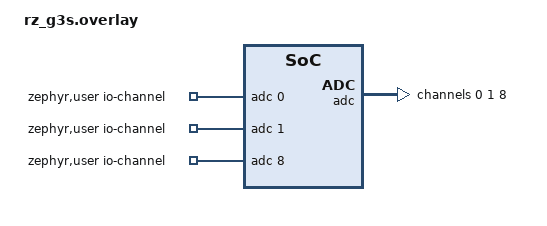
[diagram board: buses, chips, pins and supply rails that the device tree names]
/*
 * Copyright (c) 2024 EPAM Systems
 *
 * SPDX-License-Identifier: Apache-2.0
 */

/ {
	zephyr,user {
		io-channels = <&adc 0>, <&adc 1>, <&adc 8>;
	};
};

&adc {
	#address-cells = <1>;
	#size-cells = <0>;
	status = "okay";

	/* ADC_CH0 */
	channel@0 {
		reg = <0>;
		zephyr,gain = "ADC_GAIN_1";
		zephyr,reference = "ADC_REF_INTERNAL";
		zephyr,acquisition-time = <ADC_ACQ_TIME_DEFAULT>;
		zephyr,resolution = <12>;
	};

	/* ADC_CH1 */
	channel@1 {
		reg = <1>;
		zephyr,gain = "ADC_GAIN_1";
		zephyr,reference = "ADC_REF_INTERNAL";
		zephyr,acquisition-time = <ADC_ACQ_TIME_DEFAULT>;
		zephyr,resolution = <12>;
	};

	/* TSU */
	channel@8 {
		reg = <8>;
		zephyr,gain = "ADC_GAIN_1";
		zephyr,reference = "ADC_REF_INTERNAL";
		zephyr,acquisition-time = <ADC_ACQ_TIME_DEFAULT>;
		zephyr,resolution = <12>;
	};
};
